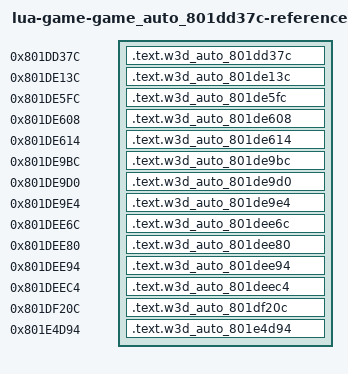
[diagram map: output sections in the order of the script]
/* Generated reference-only placements. All bodies are source-built. */
OUTPUT_FORMAT("elf32-powerpc")
OUTPUT_ARCH(powerpc)
ENTRY(w3d_auto_801dd37c)
_SDA_BASE_ = 0x804b2540;
_SDA2_BASE_ = 0x804c2540;
fn_801E4FCC = 0x801e4fcc;
fn_8020BD38 = 0x8020bd38;
SECTIONS {
  .text.w3d_auto_801dd37c 0x801dd37c : { *(.text.w3d_auto_801dd37c) }
  .text.w3d_auto_801de13c 0x801de13c : { *(.text.w3d_auto_801de13c) }
  .text.w3d_auto_801de5fc 0x801de5fc : { *(.text.w3d_auto_801de5fc) }
  .text.w3d_auto_801de608 0x801de608 : { *(.text.w3d_auto_801de608) }
  .text.w3d_auto_801de614 0x801de614 : { *(.text.w3d_auto_801de614) }
  .text.w3d_auto_801de9bc 0x801de9bc : { *(.text.w3d_auto_801de9bc) }
  .text.w3d_auto_801de9d0 0x801de9d0 : { *(.text.w3d_auto_801de9d0) }
  .text.w3d_auto_801de9e4 0x801de9e4 : { *(.text.w3d_auto_801de9e4) }
  .text.w3d_auto_801dee6c 0x801dee6c : { *(.text.w3d_auto_801dee6c) }
  .text.w3d_auto_801dee80 0x801dee80 : { *(.text.w3d_auto_801dee80) }
  .text.w3d_auto_801dee94 0x801dee94 : { *(.text.w3d_auto_801dee94) }
  .text.w3d_auto_801deec4 0x801deec4 : { *(.text.w3d_auto_801deec4) }
  .text.w3d_auto_801df20c 0x801df20c : { *(.text.w3d_auto_801df20c) }
  .text.w3d_auto_801e4d94 0x801e4d94 : { *(.text.w3d_auto_801e4d94) }
  /DISCARD/ : { *(.text*) *(.rodata*) *(.data*) *(.bss*) *(.sdata*) *(.sbss*) *(.comment) }
}
